# CBASS_MEM_CBASS_QOS_45D30000h register map
Vendor: Texas Instruments
Peripheral module from a debugger description file (folder AM275x).
Registers are 32-bit, read-write, reset 0x7000 unless marked. A register's access mark holds for its fields unless they carry their own. Offsets are as the file gives them; lines under a group give offsets from that group; [hi:lo] are bit positions; {n}, {i} and the like mark numbered series; 'fields as' and 'values as' point back to an identical list; <NAME> marks a mode.

## cbass_qos
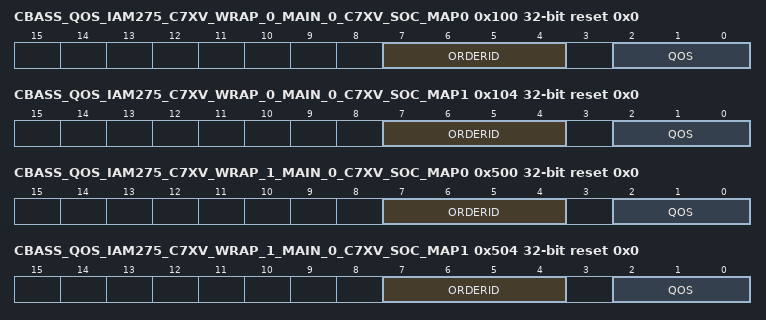
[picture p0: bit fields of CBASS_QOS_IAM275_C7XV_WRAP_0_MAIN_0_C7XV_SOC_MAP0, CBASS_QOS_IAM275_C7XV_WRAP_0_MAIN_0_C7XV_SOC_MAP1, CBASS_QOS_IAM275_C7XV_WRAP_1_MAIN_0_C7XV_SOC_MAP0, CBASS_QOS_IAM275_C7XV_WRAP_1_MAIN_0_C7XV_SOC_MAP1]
0x100 CBASS_QOS_IAM275_C7XV_WRAP_0_MAIN_0_C7XV_SOC_MAP0 reset 0x0 — The Map Register defines the fields for the initiator Iam275_c7xv_wrap_0_main_0.c7xv_soc per channel.
  [7:4] ORDERID — orderid signal for channel N.Selects to route for load balancing (0-7 uses one route, 8-15 another).Also used by DDR4/LPDDR4 re-ordering to maximize throughput. Order of transactions is only guaranteed with the same orderid Reset Source: domain_default_rst_mod_g_rst_n
  [2:0] QOS — qos signal for channel N. Reset Source: domain_default_rst_mod_g_rst_n
0x104 CBASS_QOS_IAM275_C7XV_WRAP_0_MAIN_0_C7XV_SOC_MAP1 reset 0x0 — The Map Register defines the fields for the initiator Iam275_c7xv_wrap_0_main_0.c7xv_soc per channel.
  fields as CBASS_QOS_IAM275_C7XV_WRAP_0_MAIN_0_C7XV_SOC_MAP0
0x500 CBASS_QOS_IAM275_C7XV_WRAP_1_MAIN_0_C7XV_SOC_MAP0 reset 0x0 — The Map Register defines the fields for the initiator Iam275_c7xv_wrap_1_main_0.c7xv_soc per channel.
  fields as CBASS_QOS_IAM275_C7XV_WRAP_0_MAIN_0_C7XV_SOC_MAP0
0x504 CBASS_QOS_IAM275_C7XV_WRAP_1_MAIN_0_C7XV_SOC_MAP1 reset 0x0 — The Map Register defines the fields for the initiator Iam275_c7xv_wrap_1_main_0.c7xv_soc per channel.
  fields as CBASS_QOS_IAM275_C7XV_WRAP_0_MAIN_0_C7XV_SOC_MAP0
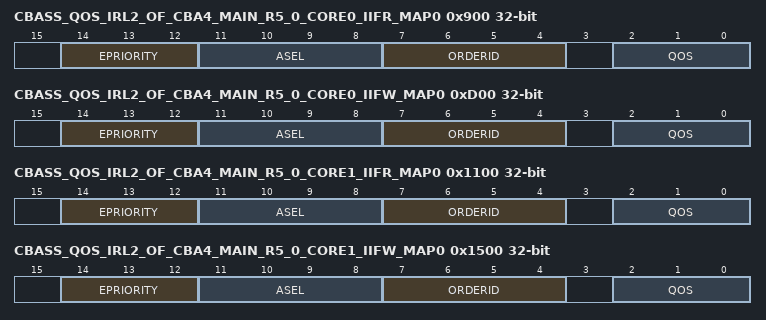
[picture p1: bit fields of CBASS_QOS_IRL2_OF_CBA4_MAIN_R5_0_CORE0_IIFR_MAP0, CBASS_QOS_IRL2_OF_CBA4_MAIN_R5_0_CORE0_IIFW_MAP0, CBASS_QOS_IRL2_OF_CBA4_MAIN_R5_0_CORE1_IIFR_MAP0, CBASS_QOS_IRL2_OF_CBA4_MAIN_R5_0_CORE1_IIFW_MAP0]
0x900 CBASS_QOS_IRL2_OF_CBA4_MAIN_R5_0_CORE0_IIFR_MAP0 — The Map Register defines the fields for the initiator Irl2_of_cba4_main_r5_0_core0.iifr per channel.
  [14:12] EPRIORITY — epriority signal for channel N.This is the strict priority arbitration priority at the destination Reset Source: domain_default_rst_mod_g_rst_n
  [11:8] ASEL — Only used for PCIe, and cache coherency with A53 ACP. So traffic to MSRAM or DDR with asel set to below values will be routed via A53 cache controller. ASEL=0 | normalASEL=1 | PCIe address space for the entire addressASEL=14 | W | cause L2 cache allocation: for cache warming featureASEL=14 | R | does not cause L2 cache allocationASEL=15 | R/W | does not cause L2 cache allocation Reset Source: domain_default_rst_mod_g_rst_n
  [7:4] ORDERID — orderid signal for channel N.Selects to route for load balancing (0-7 uses one route, 8-15 another).Also used by DDR4/LPDDR4 re-ordering to maximize throughput. Order of transactions is only guaranteed with the same orderid Reset Source: domain_default_rst_mod_g_rst_n
  [2:0] QOS — qos signal for channel N. Reset Source: domain_default_rst_mod_g_rst_n
0xD00 CBASS_QOS_IRL2_OF_CBA4_MAIN_R5_0_CORE0_IIFW_MAP0 — The Map Register defines the fields for the initiator Irl2_of_cba4_main_r5_0_core0.iifw per channel.
  fields as CBASS_QOS_IRL2_OF_CBA4_MAIN_R5_0_CORE0_IIFR_MAP0
0x1100 CBASS_QOS_IRL2_OF_CBA4_MAIN_R5_0_CORE1_IIFR_MAP0 — The Map Register defines the fields for the initiator Irl2_of_cba4_main_r5_0_core1.iifr per channel.
  fields as CBASS_QOS_IRL2_OF_CBA4_MAIN_R5_0_CORE0_IIFR_MAP0
0x1500 CBASS_QOS_IRL2_OF_CBA4_MAIN_R5_0_CORE1_IIFW_MAP0 — The Map Register defines the fields for the initiator Irl2_of_cba4_main_r5_0_core1.iifw per channel.
  fields as CBASS_QOS_IRL2_OF_CBA4_MAIN_R5_0_CORE0_IIFR_MAP0
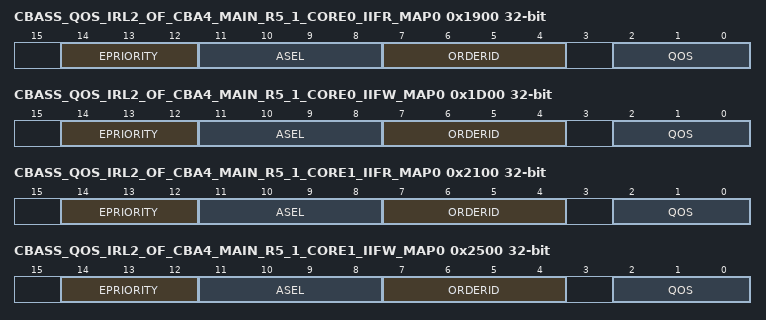
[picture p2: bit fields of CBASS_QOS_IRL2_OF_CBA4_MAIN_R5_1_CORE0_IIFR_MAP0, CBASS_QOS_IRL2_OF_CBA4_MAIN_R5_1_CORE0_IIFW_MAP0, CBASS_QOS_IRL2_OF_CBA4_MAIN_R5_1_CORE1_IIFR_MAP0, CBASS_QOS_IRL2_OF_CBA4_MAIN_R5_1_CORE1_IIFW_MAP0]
0x1900 CBASS_QOS_IRL2_OF_CBA4_MAIN_R5_1_CORE0_IIFR_MAP0 — The Map Register defines the fields for the initiator Irl2_of_cba4_main_r5_1_core0.iifr per channel.
  fields as CBASS_QOS_IRL2_OF_CBA4_MAIN_R5_0_CORE0_IIFR_MAP0
0x1D00 CBASS_QOS_IRL2_OF_CBA4_MAIN_R5_1_CORE0_IIFW_MAP0 — The Map Register defines the fields for the initiator Irl2_of_cba4_main_r5_1_core0.iifw per channel.
  fields as CBASS_QOS_IRL2_OF_CBA4_MAIN_R5_0_CORE0_IIFR_MAP0
0x2100 CBASS_QOS_IRL2_OF_CBA4_MAIN_R5_1_CORE1_IIFR_MAP0 — The Map Register defines the fields for the initiator Irl2_of_cba4_main_r5_1_core1.iifr per channel.
  fields as CBASS_QOS_IRL2_OF_CBA4_MAIN_R5_0_CORE0_IIFR_MAP0
0x2500 CBASS_QOS_IRL2_OF_CBA4_MAIN_R5_1_CORE1_IIFW_MAP0 — The Map Register defines the fields for the initiator Irl2_of_cba4_main_r5_1_core1.iifw per channel.
  fields as CBASS_QOS_IRL2_OF_CBA4_MAIN_R5_0_CORE0_IIFR_MAP0
